VERSION ""

NS_ :

BS_:

BU_: ApplicationECU TestECU

BO_ 3221225472 VECTOR__INDEPENDENT_SIG_MSG: 0 Vector__XXX
 SG_ CellTemp24 : 0|8@0- (0.5,-30) [-30|80] "¡æ" Vector__XXX

BO_ 17 EIS_Start_Rx: 8 Vector__XXX
 SG_ EIS_Start : 7|1@0+ (1,0) [0|0] ""  ApplicationECU

BO_ 442 CPU_UASGE: 8 ApplicationECU
 SG_ CPUNum : 7|4@0+ (1,0) [0|3] "" Vector__XXX
 SG_ CPU_USE : 3|8@0+ (1,0) [0|100] "%" Vector__XXX

BO_ 515 BMS_01: 8 ApplicationECU
 SG_ BMS_State : 7|4@0+ (1,0) [0|15] "enum" Vector__XXX

BO_ 427 BMS_12: 8 ApplicationECU
 SG_ BatSumDisChrgCap : 39|32@0+ (0.01,0) [0|42949673] "Ah" Vector__XXX
 SG_ BatSumChrgCap : 7|32@0+ (0.01,0) [0|42949673] "Ah" Vector__XXX

BO_ 418 BMS_03: 16 ApplicationECU
 SG_ PackSOC : 87|16@0+ (0.1,0) [0|6553.5] "kWh" Vector__XXX
 SG_ BatSOH : 71|16@0+ (1,0) [0|65535] "%" Vector__XXX
 SG_ EISBatSOH : 39|32@0+ (1,0) [0|1440] "min" Vector__XXX
 SG_ EISPackSOC : 23|16@0+ (1,0) [0|100] "%" Vector__XXX
 SG_ Conn1Number : 15|8@0+ (1,0) [0|100] "enum" Vector__XXX
 SG_ Conn2Number : 7|8@0+ (1,0) [0|250] "enum" Vector__XXX

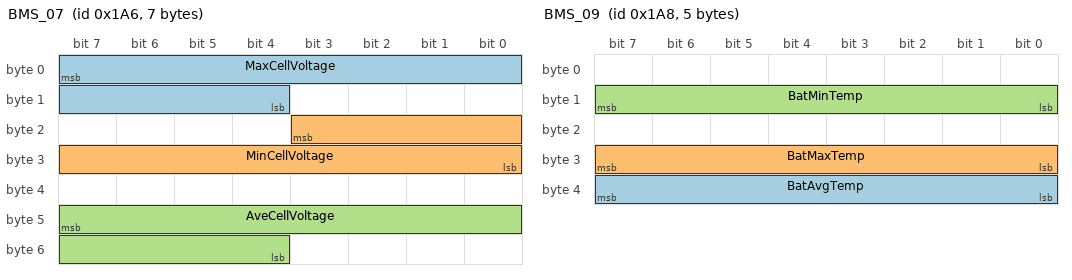
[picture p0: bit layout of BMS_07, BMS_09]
BO_ 422 BMS_07: 7 ApplicationECU
 SG_ MaxCellVoltage : 7|12@0+ (1,0) [0|5050] "mV" Vector__XXX
 SG_ MinCellVoltage : 19|12@0+ (1,0) [0|5050] "mV" Vector__XXX
 SG_ AveCellVoltage : 47|12@0+ (1,0) [0|5050] "mV" Vector__XXX

BO_ 424 BMS_09: 5 ApplicationECU
 SG_ BatAvgTemp : 39|8@0+ (0.5,-30) [-30|80] "â„ƒ" Vector__XXX
 SG_ BatMaxTemp : 31|8@0+ (0.5,-30) [-30|80] "â„ƒ" Vector__XXX
 SG_ BatMinTemp : 15|8@0+ (0.5,-30) [-30|80] "â„ƒ" Vector__XXX

BO_ 420 BMS_05: 8 ApplicationECU
 SG_ BMS_SoftVer : 7|16@0+ (1,0) [0|255] "" Vector__XXX
 SG_ BMS_HwVer : 23|16@0+ (1,0) [0|255] "" Vector__XXX

BO_ 432 BMS_CellTemp: 32 ApplicationECU
 SG_ CellTemp9 : 103|8@0+ (0.5,-30) [-30|80] "¡æ" Vector__XXX
 SG_ CellTemp8 : 95|8@0+ (0.5,-30) [-30|80] "¡æ" Vector__XXX
 SG_ CellTemp7 : 87|8@0+ (0.5,-30) [-30|80] "¡æ" Vector__XXX
 SG_ CellTemp6 : 79|8@0+ (0.5,-30) [-30|80] "¡æ" Vector__XXX
 SG_ CellTemp5 : 71|8@0+ (0.5,-30) [-30|80] "¡æ" Vector__XXX
 SG_ CellTemp4 : 63|8@0+ (0.5,-30) [-30|80] "¡æ" Vector__XXX
 SG_ CellTemp3 : 55|8@0+ (0.5,-30) [-30|80] "¡æ" Vector__XXX
 SG_ CellTemp26 : 239|8@0+ (0.5,-30) [-30|80] "¡æ" Vector__XXX
 SG_ CellTemp25 : 231|8@0+ (0.5,-30) [-30|80] "¡æ" Vector__XXX
 SG_ CellTemp24 : 223|8@0+ (0.5,-30) [-30|80] "¡æ" Vector__XXX
 SG_ CellTemp23 : 215|8@0+ (0.5,-30) [-30|80] "¡æ" Vector__XXX
 SG_ CellTemp22 : 207|8@0+ (0.5,-30) [-30|80] "¡æ" Vector__XXX
 SG_ CellTemp21 : 199|8@0+ (0.5,-30) [-30|80] "¡æ" Vector__XXX
 SG_ CellTemp20 : 191|8@0+ (0.5,-30) [-30|80] "¡æ" Vector__XXX
 SG_ CellTemp19 : 183|8@0+ (0.5,-30) [-30|80] "¡æ" Vector__XXX
 SG_ CellTemp18 : 175|8@0+ (0.5,-30) [-30|80] "¡æ" Vector__XXX
 SG_ CellTemp17 : 167|8@0+ (0.5,-30) [-30|80] "¡æ" Vector__XXX
 SG_ CellTemp16 : 159|8@0+ (0.5,-30) [-30|80] "¡æ" Vector__XXX
 SG_ CellTemp15 : 151|8@0+ (0.5,-30) [-30|80] "¡æ" Vector__XXX
 SG_ CellTemp14 : 143|8@0+ (0.5,-30) [-30|80] "¡æ" Vector__XXX
 SG_ CellTemp13 : 135|8@0+ (0.5,-30) [-30|80] "¡æ" Vector__XXX
 SG_ CellTemp12 : 127|8@0+ (0.5,-30) [-30|80] "¡æ" Vector__XXX
 SG_ CellTemp11 : 119|8@0+ (0.5,-30) [-30|80] "¡æ" Vector__XXX
 SG_ CellTemp10 : 111|8@0+ (0.5,-30) [-30|80] "¡æ" Vector__XXX
 SG_ CellTemp2 : 47|8@0+ (0.5,-30) [-30|80] "¡æ" Vector__XXX
 SG_ CellTemp1 : 39|8@0+ (0.5,-30) [-30|80] "¡æ" Vector__XXX
 SG_ BatteryBoardEnum : 15|16@0+ (1,0) [0|250] "" Vector__XXX

BO_ 437 BMS_CellVoltage: 64 ApplicationECU
 SG_ CellVoltage9 : 159|16@0+ (1,0) [0|5500] "mV" Vector__XXX
 SG_ CellVoltage8 : 143|16@0+ (1,0) [0|5500] "mV" Vector__XXX
 SG_ CellVoltage7 : 127|16@0+ (1,0) [0|5500] "mV" Vector__XXX
 SG_ CellVoltage6 : 111|16@0+ (1,0) [0|5500] "mV" Vector__XXX
 SG_ CellVoltage5 : 95|16@0+ (1,0) [0|5500] "mV" Vector__XXX
 SG_ CellVoltage4 : 79|16@0+ (1,0) [0|5500] "mV" Vector__XXX
 SG_ CellVoltage3 : 63|16@0+ (1,0) [0|5500] "mV" Vector__XXX
 SG_ CellVoltage26 : 431|16@0+ (1,0) [0|5500] "mV" Vector__XXX
 SG_ CellVoltage25 : 415|16@0+ (1,0) [0|5500] "mV" Vector__XXX
 SG_ CellVoltage24 : 399|16@0+ (1,0) [0|5500] "mV" Vector__XXX
 SG_ CellVoltage23 : 383|16@0+ (1,0) [0|5500] "mV" Vector__XXX
 SG_ CellVoltage22 : 367|16@0+ (1,0) [0|5500] "mV" Vector__XXX
 SG_ CellVoltage21 : 351|16@0+ (1,0) [0|5500] "mV" Vector__XXX
 SG_ CellVoltage20 : 335|16@0+ (1,0) [0|5500] "mV" Vector__XXX
 SG_ CellVoltage2 : 47|16@0+ (1,0) [0|5500] "mV" Vector__XXX
 SG_ CellVoltage19 : 319|16@0+ (1,0) [0|5500] "mV" Vector__XXX
 SG_ CellVoltage18 : 303|16@0+ (1,0) [0|5500] "mV" Vector__XXX
 SG_ CellVoltage17 : 287|16@0+ (1,0) [0|5500] "mV" Vector__XXX
 SG_ CellVoltage16 : 271|16@0+ (1,0) [0|5500] "mV" Vector__XXX
 SG_ CellVoltage15 : 255|16@0+ (1,0) [0|5500] "mV" Vector__XXX
 SG_ CellVoltage14 : 239|16@0+ (1,0) [0|5500] "mV" Vector__XXX
 SG_ CellVoltage13 : 223|16@0+ (1,0) [0|5500] "mV" Vector__XXX
 SG_ CellVoltage12 : 207|16@0+ (1,0) [0|5500] "mV" Vector__XXX
 SG_ CellVoltage11 : 191|16@0+ (1,0) [0|5500] "mV" Vector__XXX
 SG_ CellVoltage10 : 175|16@0+ (1,0) [0|5500] "mV" Vector__XXX
 SG_ CellVoltage1 : 31|16@0+ (1,0) [0|5500] "mV" Vector__XXX
 SG_ BatteryBoardEnum : 15|16@0+ (1,0) [0|65535] "enum" Vector__XXX

BO_ 438 BMS_Cell_SoH: 64 ApplicationECU

BO_ 439 BMS_Cell_SoC: 64 ApplicationECU
 SG_ CellSOC24 : 223|8@0+ (1,0) [0|100] "" Vector__XXX
 SG_ CellSOC9 : 103|8@0+ (1,0) [0|100] "" Vector__XXX
 SG_ CellSOC8 : 95|8@0+ (1,0) [0|100] "" Vector__XXX
 SG_ CellSOC7 : 87|8@0+ (1,0) [0|100] "" Vector__XXX
 SG_ CellSOC6 : 79|8@0+ (1,0) [0|100] "" Vector__XXX
 SG_ CellSOC5 : 71|8@0+ (1,0) [0|100] "" Vector__XXX
 SG_ CellSOC4 : 63|8@0+ (1,0) [0|100] "" Vector__XXX
 SG_ CellSOC3 : 55|8@0+ (1,0) [0|100] "" Vector__XXX
 SG_ CellSOC26 : 239|8@0+ (1,0) [0|100] "" Vector__XXX
 SG_ CellSOC25 : 231|8@0+ (1,0) [0|100] "" Vector__XXX
 SG_ CellSOC23 : 215|8@0+ (1,0) [0|100] "" Vector__XXX
 SG_ CellSOC22 : 207|8@0+ (1,0) [0|100] "" Vector__XXX
 SG_ CellSOC21 : 199|8@0+ (1,0) [0|100] "" Vector__XXX
 SG_ CellSOC20 : 191|8@0+ (1,0) [0|100] "" Vector__XXX
 SG_ CellSOC2 : 47|8@0+ (1,0) [0|100] "" Vector__XXX
 SG_ CellSOC19 : 183|8@0+ (1,0) [0|100] "" Vector__XXX
 SG_ CellSOC18 : 175|8@0+ (1,0) [0|100] "" Vector__XXX
 SG_ CellSOC17 : 167|8@0+ (1,0) [0|100] "" Vector__XXX
 SG_ CellSOC16 : 159|8@0+ (1,0) [0|100] "" Vector__XXX
 SG_ CellSOC15 : 151|8@0+ (1,0) [0|100] "" Vector__XXX
 SG_ CellSOC14 : 143|8@0+ (1,0) [0|100] "" Vector__XXX
 SG_ CellSOC13 : 135|8@0+ (1,0) [0|100] "" Vector__XXX
 SG_ CellSOC12 : 127|8@0+ (1,0) [0|100] "" Vector__XXX
 SG_ CellSOC11 : 119|8@0+ (1,0) [0|100] "" Vector__XXX
 SG_ CellSOC10 : 111|8@0+ (1,0) [0|100] "" Vector__XXX
 SG_ CellSOC1 : 39|8@0+ (1,0) [0|100] "" Vector__XXX
 SG_ BatteryBoardEnum : 15|16@0+ (1,0) [0|65535] "" Vector__XXX

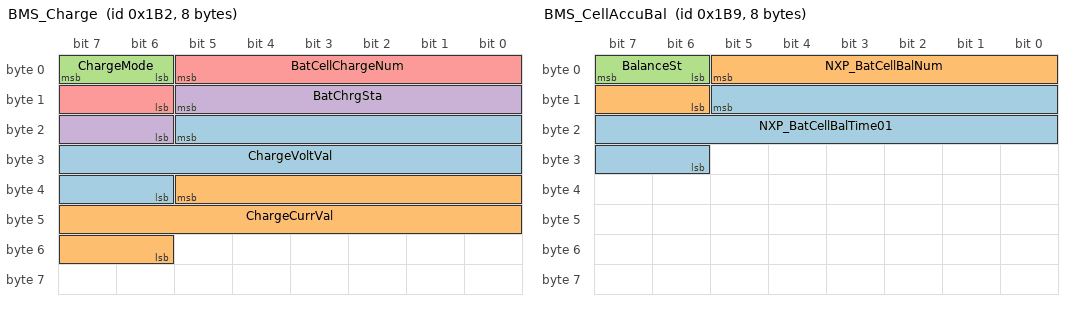
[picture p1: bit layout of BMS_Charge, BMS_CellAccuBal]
BO_ 434 BMS_Charge: 8 ApplicationECU
 SG_ ChargeVoltVal : 21|16@0+ (0.1,0) [0|1000] "V" Vector__XXX
 SG_ ChargeCurrVal : 37|16@0+ (0.1,-400) [0|500] "A" Vector__XXX
 SG_ ChargeMode : 7|2@0+ (1,0) [0|3] "" Vector__XXX
 SG_ BatChrgSta : 13|8@0+ (1,0) [0|0] "" Vector__XXX
 SG_ BatCellChargeNum : 5|8@0+ (1,0) [0|24] "enum" Vector__XXX

BO_ 441 BMS_CellAccuBal: 8 ApplicationECU
 SG_ NXP_BatCellBalTime01 : 13|16@0+ (1,0) [0|65535] "" Vector__XXX
 SG_ NXP_BatCellBalNum : 5|8@0+ (1,0) [0|255] "" Vector__XXX
 SG_ BalanceSt : 7|2@0+ (1,0) [0|3] "" Vector__XXX

BO_ 440 BMS_EIS: 32 ApplicationECU
 SG_ EISCnt : 127|16@0+ (1,0) [0|65535] "s" Vector__XXX
 SG_ EISFinish : 119|8@0+ (1,0) [0|0] "" Vector__XXX
 SG_ BatEISSta : 111|8@0+ (1,0) [0|0] "" Vector__XXX
 SG_ Bat_EIS_Freq : 79|32@0+ (0.01,0) [0|42949672.95] "Hz" Vector__XXX
 SG_ Bat_EIS_CelNum : 71|8@0+ (1,0) [0|255] "" Vector__XXX
 SG_ BatCell_EIS_Z_Real : 39|32@0- (1,0) [0|4294967295] "Î¼Î©" Vector__XXX
 SG_ BatCell_EIS_Z_Imag : 7|32@0- (1,0) [0|4294967295] "Î¼Î©" Vector__XXX

BO_ 436 BMS_DIAG: 8 ApplicationECU
 SG_ BatFaultCode1 : 3|8@0+ (1,0) [0|255] "" Vector__XXX
 SG_ BatFaultLevel : 7|4@0+ (1,0) [0|15] "" Vector__XXX

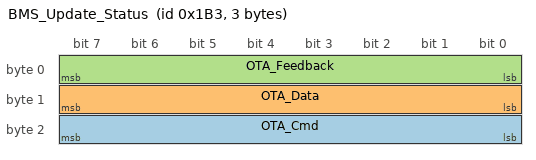
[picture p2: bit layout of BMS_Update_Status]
BO_ 435 BMS_Update_Status: 3 ApplicationECU
 SG_ OTA_Cmd : 23|8@0+ (1,0) [0|15] "" Vector__XXX
 SG_ OTA_Data : 15|8@0+ (1,0) [0|15] "" Vector__XXX
 SG_ OTA_Feedback : 7|8@0+ (1,0) [0|15] "" Vector__XXX

BO_ 10 ApplicationECU_TestResult_Tx: 8 ApplicationECU
 SG_ ApplicationECU_SG_TestResult_Tx : 0|8@1- (1,0) [0|0] ""  TestECU
 SG_ ApplicationECU_SG_TestResultData : 8|8@1- (1,0) [0|0] ""  TestECU

BO_ 20 TestECU_TestCode_Tx: 8 TestECU
 SG_ TestECU_SG_TestCode_Tx : 0|8@1- (1,0) [0|0] ""  ApplicationECU
 SG_ TestECU_SG_TestCodeData_Tx : 8|8@1- (1,0) [0|0] ""  ApplicationECU

BO_ 1264 UDS_RX_FUNC: 8 TestECU
 SG_ UDS_RX_FUNC_SIGNAL : 0|8@1- (1,0) [0|0] ""  ApplicationECU

BO_ 1248 UDS_RX_PHY: 8 TestECU
 SG_ UDS_RX_PHY_SIGNAL : 0|8@1- (1,0) [0|0] ""  ApplicationECU

BO_ 1232 UDS_TX: 8 ApplicationECU
 SG_ UDS_TX_SIGNAL : 0|8@1- (1,0) [0|0] ""  TestECU

BO_ 2015 Diag_OBD_ON_CAN_Rx: 8 TestECU
 SG_ OBD_RX_SIGNAL : 0|8@1- (1,0) [0|0] ""  ApplicationECU

BO_ 2024 Diag_OBD_ON_CAN_Tx: 8 ApplicationECU
 SG_ OBD_TX_SIGNAL : 0|8@1- (1,0) [0|0] ""  TestECU

BO_ 254 ApplicationECU_TestResFD_Tx: 16 ApplicationECU
 SG_ ApplicationECU_SG_TestResFD_Tx : 0|8@1- (1,0) [0|0] ""  TestECU

BO_ 253 TestECU_TestCodeFD_Tx: 16 TestECU
 SG_ TestECU_SG_TestCodeFD_Tx : 0|8@1- (1,0) [0|0] ""  ApplicationECU

CM_ "Author:Xiaoshuai ;
";
CM_ BO_ 3221225472 "This is a message for not used signals, created by Vector CANdb++ DBC OLE DB Provider.";
CM_ SG_ 515 BMS_State "BMS State";
CM_ SG_ 427 BatSumDisChrgCap "Total Discharge Capacity";
CM_ SG_ 427 BatSumChrgCap "Total Charge Capacity";
CM_ SG_ 418 PackSOC "Remaining Available Energy";
CM_ SG_ 418 BatSOH "SOH";
CM_ SG_ 418 EISBatSOH "Remaining Charging Time";
CM_ SG_ 418 EISPackSOC "Real SOC";
CM_ SG_ 418 Conn1Number "Number of Connected Chips";
CM_ SG_ 418 Conn2Number "Number of Connected Battery Cells";
CM_ SG_ 422 MaxCellVoltage "Maximum Cell Voltage";
CM_ SG_ 422 MinCellVoltage "Minimum Cell Voltage";
CM_ SG_ 422 AveCellVoltage "Average Cell Voltage";
CM_ SG_ 424 BatAvgTemp "Average Battery Temperature";
CM_ SG_ 424 BatMaxTemp "Maximum Cell Temperature";
CM_ SG_ 424 BatMinTemp "Minimum Cell Temperature";
CM_ SG_ 420 BMS_SoftVer "Software Version";
CM_ SG_ 420 BMS_HwVer "Hardware Version";
CM_ SG_ 432 CellTemp1 "Cell Temperature";
CM_ SG_ 432 BatteryBoardEnum "Cell Temperature Number";
CM_ SG_ 437 CellVoltage1 "Cell Voltage";
CM_ SG_ 437 BatteryBoardEnum "Cell Voltage Number";
CM_ SG_ 439 BatteryBoardEnum "Cell State of Charge";
CM_ SG_ 434 ChargeVoltVal "Charging Voltage";
CM_ SG_ 434 ChargeCurrVal "Charging Current";
CM_ SG_ 434 ChargeMode "Charging Mode";
CM_ SG_ 434 BatChrgSta "Battery Charging Status";
CM_ SG_ 434 BatCellChargeNum "Cell Charging Number";
CM_ SG_ 441 NXP_BatCellBalTime01 "Remaining Cell Balancing Time(x=NXP_BatCellBalNum)";
CM_ SG_ 441 NXP_BatCellBalNum "Cell Balancing Number";
CM_ SG_ 441 BalanceSt "Balancing Status";
CM_ SG_ 440 EISCnt "EIS Sampling Counter";
CM_ SG_ 440 EISFinish "EIS Sampling Completion Flag";
CM_ SG_ 440 BatEISSta "EIS Sampling Status";
CM_ SG_ 440 Bat_EIS_Freq "EIS Excitation Frequency";
CM_ SG_ 440 Bat_EIS_CelNum "EIS Cell Number";
CM_ SG_ 440 BatCell_EIS_Z_Real "EIS Real Part Impedance";
CM_ SG_ 440 BatCell_EIS_Z_Imag "EIS Imaginary Part Impedance";
CM_ SG_ 436 BatFaultCode1 "Fault Code";
CM_ SG_ 436 BatFaultLevel "Fault Level";
CM_ SG_ 435 OTA_Cmd "OTA Update Command";
CM_ SG_ 435 OTA_Data "OTA Update Data";
CM_ SG_ 435 OTA_Feedback "OTA Update Feedback";
BA_DEF_  "BusType" STRING ;
BA_DEF_ BO_  "VFrameFormat" ENUM  "StandardCAN","ExtendedCAN","reserved","reserved","reserved","reserved","reserved","reserved","reserved","reserved","reserved","reserved","reserved","reserved","StandardCAN_FD","ExtendedCAN_FD";
BA_DEF_ BO_  "DiagResponse" ENUM  "no","yes";
BA_DEF_ BO_  "DiagRequest" ENUM  "no","yes";
BA_DEF_  "SamplePointMax" FLOAT 0 100;
BA_DEF_ BU_  "NodeLayerModules" STRING ;
BA_DEF_ BO_  "GenMsgILSupport" ENUM  "No","Yes";
BA_DEF_  "NmBaseAddress" HEX 1024 1087;
BA_DEF_ BO_  "GenMsgCycleTime" INT 0 50000;
BA_DEF_ BO_  "GenMsgSendType" ENUM  "Cyclic","NotUsed","NotUsed","NotUsed","NotUsed","NotUsed","NotUsed","IfActive","NoMsgSendType","NotUsed","vector_leerstring";
BA_DEF_ SG_  "GenSigSendType" ENUM  "Cyclic","OnWrite","OnWriteWithRepetition","OnChange","OnChangeWithRepetition","IfActive","IfActiveWithRepetition","NoSigSendType","NotUsed","NotUsed","NotUsed","NotUsed","NotUsed";
BA_DEF_ SG_  "GenSigStartValue" FLOAT 0 100000000000;
BA_DEF_DEF_  "BusType" "CAN FD";
BA_DEF_DEF_  "VFrameFormat" "StandardCAN";
BA_DEF_DEF_  "DiagResponse" "";
BA_DEF_DEF_  "DiagRequest" "";
BA_DEF_DEF_  "SamplePointMax" 81.4;
BA_DEF_DEF_  "NodeLayerModules" "CANoeILNLVector.dll";
BA_DEF_DEF_  "GenMsgILSupport" "Yes";
BA_DEF_DEF_  "NmBaseAddress" 1024;
BA_DEF_DEF_  "GenMsgCycleTime" 100;
BA_DEF_DEF_  "GenMsgSendType" "Cyclic";
BA_DEF_DEF_  "GenSigSendType" "Cyclic";
BA_DEF_DEF_  "GenSigStartValue" 0;
BA_ "VFrameFormat" BO_ 442 14;
BA_ "GenMsgCycleTime" BO_ 515 10;
BA_ "VFrameFormat" BO_ 515 14;
BA_ "GenMsgCycleTime" BO_ 427 1000;
BA_ "VFrameFormat" BO_ 427 14;
BA_ "VFrameFormat" BO_ 418 14;
BA_ "VFrameFormat" BO_ 422 14;
BA_ "VFrameFormat" BO_ 424 14;
BA_ "GenMsgCycleTime" BO_ 420 50;
BA_ "VFrameFormat" BO_ 420 14;
BA_ "GenMsgCycleTime" BO_ 432 50;
BA_ "VFrameFormat" BO_ 432 14;
BA_ "GenMsgCycleTime" BO_ 437 10;
BA_ "VFrameFormat" BO_ 437 14;
BA_ "GenMsgCycleTime" BO_ 438 10;
BA_ "VFrameFormat" BO_ 438 14;
BA_ "GenMsgCycleTime" BO_ 439 10;
BA_ "VFrameFormat" BO_ 439 14;
BA_ "GenMsgCycleTime" BO_ 434 1000;
BA_ "VFrameFormat" BO_ 434 14;
BA_ "VFrameFormat" BO_ 441 14;
BA_ "GenMsgCycleTime" BO_ 440 50;
BA_ "VFrameFormat" BO_ 440 14;
BA_ "VFrameFormat" BO_ 436 14;
BA_ "VFrameFormat" BO_ 435 14;
BA_ "VFrameFormat" BO_ 10 14;
BA_ "VFrameFormat" BO_ 20 14;
BA_ "DiagRequest" BO_ 1264 1;
BA_ "VFrameFormat" BO_ 1264 14;
BA_ "DiagRequest" BO_ 1248 1;
BA_ "VFrameFormat" BO_ 1248 14;
BA_ "DiagResponse" BO_ 1232 1;
BA_ "VFrameFormat" BO_ 1232 14;
BA_ "DiagRequest" BO_ 2015 1;
BA_ "VFrameFormat" BO_ 2015 14;
BA_ "DiagResponse" BO_ 2024 1;
BA_ "VFrameFormat" BO_ 2024 14;
BA_ "VFrameFormat" BO_ 254 14;
BA_ "VFrameFormat" BO_ 253 14;
BA_ "GenSigStartValue" SG_ 3221225472 CellTemp24 60;
BA_ "GenSigStartValue" SG_ 424 BatAvgTemp 60;
BA_ "GenSigStartValue" SG_ 424 BatMaxTemp 60;
BA_ "GenSigStartValue" SG_ 424 BatMinTemp 60;
BA_ "GenSigStartValue" SG_ 432 CellTemp9 60;
BA_ "GenSigStartValue" SG_ 432 CellTemp8 60;
BA_ "GenSigStartValue" SG_ 432 CellTemp7 60;
BA_ "GenSigStartValue" SG_ 432 CellTemp6 60;
BA_ "GenSigStartValue" SG_ 432 CellTemp5 60;
BA_ "GenSigStartValue" SG_ 432 CellTemp4 60;
BA_ "GenSigStartValue" SG_ 432 CellTemp3 60;
BA_ "GenSigStartValue" SG_ 432 CellTemp26 60;
BA_ "GenSigStartValue" SG_ 432 CellTemp25 60;
BA_ "GenSigStartValue" SG_ 432 CellTemp24 60;
BA_ "GenSigStartValue" SG_ 432 CellTemp23 60;
BA_ "GenSigStartValue" SG_ 432 CellTemp22 60;
BA_ "GenSigStartValue" SG_ 432 CellTemp21 60;
BA_ "GenSigStartValue" SG_ 432 CellTemp20 60;
BA_ "GenSigStartValue" SG_ 432 CellTemp19 60;
BA_ "GenSigStartValue" SG_ 432 CellTemp18 60;
BA_ "GenSigStartValue" SG_ 432 CellTemp17 60;
BA_ "GenSigStartValue" SG_ 432 CellTemp16 60;
BA_ "GenSigStartValue" SG_ 432 CellTemp15 60;
BA_ "GenSigStartValue" SG_ 432 CellTemp14 60;
BA_ "GenSigStartValue" SG_ 432 CellTemp13 60;
BA_ "GenSigStartValue" SG_ 432 CellTemp12 60;
BA_ "GenSigStartValue" SG_ 432 CellTemp11 60;
BA_ "GenSigStartValue" SG_ 432 CellTemp10 60;
BA_ "GenSigStartValue" SG_ 432 CellTemp2 60;
BA_ "GenSigStartValue" SG_ 432 CellTemp1 60;
VAL_ 515 BMS_State 0 " DEFAULT " 1 " INITIALIZING " 2 " STANDBY " 3 " CONNECTED " 4 " SHUTDOWN " 5 " INIT_FAILED " 6 " MONITORING " 7 " UPDATING " 15 " RESERVED " ;
VAL_ 434 ChargeMode 0 " Constant Voltage" 1 " Constant Current" 2 " Reserved" 3 " Reserved" ;
VAL_ 434 BatChrgSta 0 " Idle" 1 " Charging" 2 " Discharging" ;
VAL_ 441 BalanceSt 0 " No Balance" 1 " Open" 2 " False" 3 " Reserved" ;
VAL_ 440 EISFinish 0 " Sampling In Progress" 1 " Sampling Completed" ;
VAL_ 440 BatEISSta 0 " EIS Disabled" 1 " EIS Enabled" ;
VAL_ 435 OTA_Feedback 0 " Idle" 1 " Receiving" 2 " Success" 3 " Fail" ;
